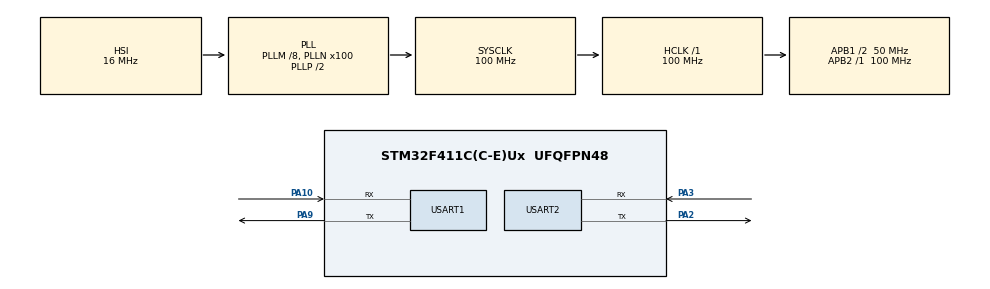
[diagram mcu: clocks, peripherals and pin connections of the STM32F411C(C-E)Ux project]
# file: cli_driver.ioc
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Dma.Request0=USART1_RX
Dma.Request1=USART1_TX
Dma.Request2=USART2_TX
Dma.Request3=USART2_RX
Dma.USART1_RX.0.Direction=DMA_PERIPH_TO_MEMORY
Dma.USART1_RX.0.FIFOMode=DMA_FIFOMODE_DISABLE
Dma.USART1_RX.0.Instance=DMA2_Stream2
Dma.USART1_RX.0.MemDataAlignment=DMA_MDATAALIGN_BYTE
Dma.USART1_RX.0.MemInc=DMA_MINC_ENABLE
Dma.USART1_RX.0.Mode=DMA_NORMAL
Dma.USART1_RX.0.PeriphDataAlignment=DMA_PDATAALIGN_BYTE
Dma.USART1_RX.0.PeriphInc=DMA_PINC_DISABLE
Dma.USART1_RX.0.Priority=DMA_PRIORITY_LOW
Dma.USART1_TX.1.Direction=DMA_MEMORY_TO_PERIPH
Dma.USART1_TX.1.FIFOMode=DMA_FIFOMODE_DISABLE
Dma.USART1_TX.1.Instance=DMA2_Stream7
Dma.USART1_TX.1.MemDataAlignment=DMA_MDATAALIGN_BYTE
Dma.USART1_TX.1.MemInc=DMA_MINC_ENABLE
Dma.USART1_TX.1.Mode=DMA_NORMAL
Dma.USART1_TX.1.PeriphDataAlignment=DMA_PDATAALIGN_BYTE
Dma.USART1_TX.1.PeriphInc=DMA_PINC_DISABLE
Dma.USART1_TX.1.Priority=DMA_PRIORITY_LOW
Dma.USART2_RX.3.Direction=DMA_PERIPH_TO_MEMORY
Dma.USART2_RX.3.FIFOMode=DMA_FIFOMODE_DISABLE
Dma.USART2_RX.3.Instance=DMA1_Stream5
Dma.USART2_RX.3.MemDataAlignment=DMA_MDATAALIGN_BYTE
Dma.USART2_RX.3.MemInc=DMA_MINC_ENABLE
Dma.USART2_RX.3.Mode=DMA_NORMAL
Dma.USART2_RX.3.PeriphDataAlignment=DMA_PDATAALIGN_BYTE
Dma.USART2_RX.3.PeriphInc=DMA_PINC_DISABLE
Dma.USART2_RX.3.Priority=DMA_PRIORITY_LOW
Dma.USART2_TX.2.Direction=DMA_MEMORY_TO_PERIPH
Dma.USART2_TX.2.FIFOMode=DMA_FIFOMODE_DISABLE
Dma.USART2_TX.2.Instance=DMA1_Stream6
Dma.USART2_TX.2.MemDataAlignment=DMA_MDATAALIGN_BYTE
Dma.USART2_TX.2.MemInc=DMA_MINC_ENABLE
Dma.USART2_TX.2.Mode=DMA_NORMAL
Dma.USART2_TX.2.PeriphDataAlignment=DMA_PDATAALIGN_BYTE
Dma.USART2_TX.2.PeriphInc=DMA_PINC_DISABLE
Dma.USART2_TX.2.Priority=DMA_PRIORITY_LOW
FREERTOS.INCLUDE_uxTaskGetStackHighWaterMark2=1
FREERTOS.Tasks01=defaultTask,24,128,StartDefaultTask,Default,NULL,Dynamic,NULL,NULL
FREERTOS.configENABLE_FPU=1
Mcu.Family=STM32F4
Mcu.Name=STM32F411C(C-E)Ux
Mcu.Package=UFQFPN48
NVIC.DMA1_Stream5_IRQn=true\:5\:0\:false\:false\:true\:true\:false\:true\:true
NVIC.DMA1_Stream6_IRQn=true\:5\:0\:false\:false\:true\:true\:false\:true\:true
NVIC.DMA2_Stream2_IRQn=true\:5\:0\:false\:false\:true\:true\:false\:true\:true
NVIC.DMA2_Stream7_IRQn=true\:5\:0\:false\:false\:true\:true\:false\:true\:true
NVIC.PriorityGroup=NVIC_PRIORITYGROUP_4
NVIC.TIM1_UP_TIM10_IRQn=true\:15\:0\:false\:false\:true\:false\:false\:true\:true
NVIC.TimeBase=TIM1_UP_TIM10_IRQn
NVIC.TimeBaseIP=TIM1
NVIC.USART1_IRQn=true\:5\:0\:false\:false\:true\:true\:true\:true\:true
NVIC.USART2_IRQn=true\:5\:0\:false\:false\:true\:true\:true\:true\:true
PA10.Mode=Asynchronous
PA10.Signal=USART1_RX
PA13.Mode=Serial_Wire
PA13.Signal=SYS_JTMS-SWDIO
PA14.Mode=Serial_Wire
PA14.Signal=SYS_JTCK-SWCLK
PA2.Mode=Asynchronous
PA2.Signal=USART2_TX
PA3.Mode=Asynchronous
PA3.Signal=USART2_RX
PA9.Mode=Asynchronous
PA9.Signal=USART1_TX
PH0\ -\ OSC_IN.Mode=HSE-External-Oscillator
PH0\ -\ OSC_IN.Signal=RCC_OSC_IN
PH1\ -\ OSC_OUT.Mode=HSE-External-Oscillator
PH1\ -\ OSC_OUT.Signal=RCC_OSC_OUT
ProjectManager.HeapSize=0x200
ProjectManager.StackSize=0x400
ProjectManager.TargetToolchain=CMake
RCC.48MHZClocksFreq_Value=50000000
RCC.AHBFreq_Value=100000000
RCC.APB1CLKDivider=RCC_HCLK_DIV2
RCC.APB1Freq_Value=50000000
RCC.APB1TimFreq_Value=100000000
RCC.APB2Freq_Value=100000000
RCC.APB2TimFreq_Value=100000000
RCC.CortexFreq_Value=100000000
RCC.HCLKFreq_Value=100000000
RCC.HSE_VALUE=25000000
RCC.HSI_VALUE=16000000
RCC.LSE_VALUE=32768
RCC.PLLM=8
RCC.PLLN=100
RCC.SYSCLKFreq_VALUE=100000000
RCC.SYSCLKSource=RCC_SYSCLKSOURCE_PLLCLK
RCC.VCOOutputFreq_Value=200000000
USART1.VirtualMode=VM_ASYNC
USART2.VirtualMode=VM_ASYNC
VP_FREERTOS_VS_CMSIS_V2.Mode=CMSIS_V2
VP_SYS_VS_tim1.Mode=TIM1
board=custom

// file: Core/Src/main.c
/* USER CODE BEGIN Header */
/**
  ******************************************************************************
  * @file           : main.c
  * @brief          : Main program body
  ******************************************************************************
  * @attention
  *
  * Copyright (c) 2026 STMicroelectronics.
  * All rights reserved.
  *
  * This software is licensed under terms that can be found in the LICENSE file
  * in the root directory of this software component.
  * If no LICENSE file comes with this software, it is provided AS-IS.
  *
  ******************************************************************************
  */
/* USER CODE END Header */
#include "main.h"
#include "cmsis_os.h"

UART_HandleTypeDef huart1;
UART_HandleTypeDef huart2;
DMA_HandleTypeDef hdma_usart1_rx;
DMA_HandleTypeDef hdma_usart1_tx;
DMA_HandleTypeDef hdma_usart2_tx;
DMA_HandleTypeDef hdma_usart2_rx;

/* Definitions for defaultTask */
osThreadId_t defaultTaskHandle;
const osThreadAttr_t defaultTask_attributes = {
  .name = "defaultTask",
  .stack_size = 65 * 4,
  .priority = (osPriority_t) osPriorityNormal,
};

void SystemClock_Config(void);
static void MX_GPIO_Init(void);
static void MX_DMA_Init(void);
static void MX_USART1_UART_Init(void);
static void MX_USART2_UART_Init(void);
void StartDefaultTask(void *argument);

/* USER CODE BEGIN 0 */

#include "app/startup.h"

/* USER CODE END 0 */

int main(void)
{

  /* MCU Configuration--------------------------------------------------------*/

  /* Reset of all peripherals, Initializes the Flash interface and the Systick. */
  HAL_Init();

  /* Configure the system clock */
  SystemClock_Config();

  /* Initialize all configured peripherals */
  MX_GPIO_Init();
  MX_DMA_Init();
  MX_USART1_UART_Init();
  MX_USART2_UART_Init();

  /* Init scheduler */
  osKernelInitialize();

  /* Create the thread(s) */
  /* creation of defaultTask */
  defaultTaskHandle = osThreadNew(StartDefaultTask, NULL, &defaultTask_attributes);

  /* USER CODE BEGIN RTOS_THREADS */

  startup_Init(&huart1); // Initialize the application with huart1

  /* USER CODE END RTOS_THREADS */

  /* Start scheduler */
  osKernelStart();

  /* We should never get here as control is now taken by the scheduler */

  /* Infinite loop */
  while (1)
  {

  }
}

void SystemClock_Config(void)
{
  RCC_OscInitTypeDef RCC_OscInitStruct = {0};
  RCC_ClkInitTypeDef RCC_ClkInitStruct = {0};

  /** Configure the main internal regulator output voltage
  */
  __HAL_RCC_PWR_CLK_ENABLE();
  __HAL_PWR_VOLTAGESCALING_CONFIG(PWR_REGULATOR_VOLTAGE_SCALE1);

  /** Initializes the RCC Oscillators according to the specified parameters
  * in the RCC_OscInitTypeDef structure.
  */
  RCC_OscInitStruct.OscillatorType = RCC_OSCILLATORTYPE_HSI;
  RCC_OscInitStruct.HSIState = RCC_HSI_ON;
  RCC_OscInitStruct.HSICalibrationValue = RCC_HSICALIBRATION_DEFAULT;
  RCC_OscInitStruct.PLL.PLLState = RCC_PLL_ON;
  RCC_OscInitStruct.PLL.PLLSource = RCC_PLLSOURCE_HSI;
  RCC_OscInitStruct.PLL.PLLM = 8;
  RCC_OscInitStruct.PLL.PLLN = 100;
  RCC_OscInitStruct.PLL.PLLP = RCC_PLLP_DIV2;
  RCC_OscInitStruct.PLL.PLLQ = 4;
  if (HAL_RCC_OscConfig(&RCC_OscInitStruct) != HAL_OK)
  {
    Error_Handler();
  }

  /** Initializes the CPU, AHB and APB buses clocks
  */
  RCC_ClkInitStruct.ClockType = RCC_CLOCKTYPE_HCLK|RCC_CLOCKTYPE_SYSCLK
                              |RCC_CLOCKTYPE_PCLK1|RCC_CLOCKTYPE_PCLK2;
  RCC_ClkInitStruct.SYSCLKSource = RCC_SYSCLKSOURCE_PLLCLK;
  RCC_ClkInitStruct.AHBCLKDivider = RCC_SYSCLK_DIV1;
  RCC_ClkInitStruct.APB1CLKDivider = RCC_HCLK_DIV2;
  RCC_ClkInitStruct.APB2CLKDivider = RCC_HCLK_DIV1;

  if (HAL_RCC_ClockConfig(&RCC_ClkInitStruct, FLASH_LATENCY_3) != HAL_OK)
  {
    Error_Handler();
  }
}

static void MX_USART1_UART_Init(void)
{

  huart1.Instance = USART1;
  huart1.Init.BaudRate = 115200;
  huart1.Init.WordLength = UART_WORDLENGTH_8B;
  huart1.Init.StopBits = UART_STOPBITS_1;
  huart1.Init.Parity = UART_PARITY_NONE;
  huart1.Init.Mode = UART_MODE_TX_RX;
  huart1.Init.HwFlowCtl = UART_HWCONTROL_NONE;
  huart1.Init.OverSampling = UART_OVERSAMPLING_16;
  if (HAL_UART_Init(&huart1) != HAL_OK)
  {
    Error_Handler();
  }

}

static void MX_USART2_UART_Init(void)
{

  huart2.Instance = USART2;
  huart2.Init.BaudRate = 115200;
  huart2.Init.WordLength = UART_WORDLENGTH_8B;
  huart2.Init.StopBits = UART_STOPBITS_1;
  huart2.Init.Parity = UART_PARITY_NONE;
  huart2.Init.Mode = UART_MODE_TX_RX;
  huart2.Init.HwFlowCtl = UART_HWCONTROL_NONE;
  huart2.Init.OverSampling = UART_OVERSAMPLING_16;
  if (HAL_UART_Init(&huart2) != HAL_OK)
  {
    Error_Handler();
  }

}

static void MX_DMA_Init(void)
{

  /* DMA controller clock enable */
  __HAL_RCC_DMA2_CLK_ENABLE();
  __HAL_RCC_DMA1_CLK_ENABLE();

  /* DMA interrupt init */
  /* DMA1_Stream5_IRQn interrupt configuration */
  HAL_NVIC_SetPriority(DMA1_Stream5_IRQn, 5, 0);
  HAL_NVIC_EnableIRQ(DMA1_Stream5_IRQn);
  /* DMA1_Stream6_IRQn interrupt configuration */
  HAL_NVIC_SetPriority(DMA1_Stream6_IRQn, 5, 0);
  HAL_NVIC_EnableIRQ(DMA1_Stream6_IRQn);
  /* DMA2_Stream2_IRQn interrupt configuration */
  HAL_NVIC_SetPriority(DMA2_Stream2_IRQn, 5, 0);
  HAL_NVIC_EnableIRQ(DMA2_Stream2_IRQn);
  /* DMA2_Stream7_IRQn interrupt configuration */
  HAL_NVIC_SetPriority(DMA2_Stream7_IRQn, 5, 0);
  HAL_NVIC_EnableIRQ(DMA2_Stream7_IRQn);

}

static void MX_GPIO_Init(void)
{

  /* GPIO Ports Clock Enable */
  __HAL_RCC_GPIOH_CLK_ENABLE();
  __HAL_RCC_GPIOA_CLK_ENABLE();

}

void StartDefaultTask(void *argument)
{
  /* USER CODE BEGIN 5 */
  for(;;)
  {

    osDelay(10000); // Delay for 10 seconds
  }
  /* USER CODE END 5 */
}

void HAL_TIM_PeriodElapsedCallback(TIM_HandleTypeDef *htim)
{
  if (htim->Instance == TIM1)
  {
    HAL_IncTick();
  }
}

void Error_Handler(void)
{
  __disable_irq();
  while (1)
  {
  }
}
